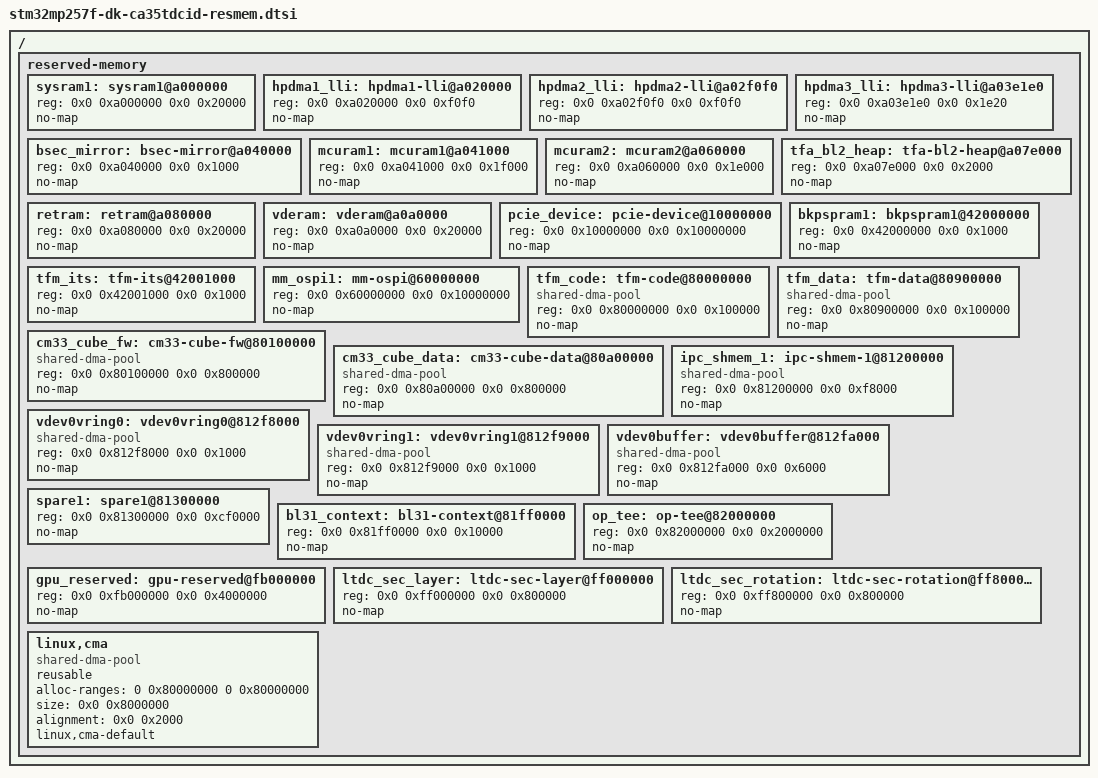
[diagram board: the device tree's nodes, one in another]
// SPDX-License-Identifier: (GPL-2.0-or-later OR BSD-3-Clause)
/*
 * Copyright (C) STMicroelectronics 2022 - All Rights Reserved
 * Author: Loic Pallardy loic.pallardy@foss.st.com for STMicroelectronics.
 */

/*
 * STM32MP25 reserved memory device tree configuration
 * Project : open
 * Generated by XLmx tool version 2.2 - 7/4/2023 9:06:24 AM
 */

/ {
	reserved-memory {
		#address-cells = <2>;
		#size-cells = <2>;
		ranges;

		/* Internal RAM reserved memory declaration */
		sysram1: sysram1@a000000 {
			reg = <0x0 0xa000000 0x0 0x20000>;
			no-map;
		};

		hpdma1_lli: hpdma1-lli@a020000 {
			reg = <0x0 0xa020000 0x0 0xf0f0>;
			no-map;
		};

		hpdma2_lli: hpdma2-lli@a02f0f0 {
			reg = <0x0 0xa02f0f0 0x0 0xf0f0>;
			no-map;
		};

		hpdma3_lli: hpdma3-lli@a03e1e0 {
			reg = <0x0 0xa03e1e0 0x0 0x1e20>;
			no-map;
		};

		bsec_mirror: bsec-mirror@a040000 {
			reg = <0x0 0xa040000 0x0 0x1000>;
			no-map;
		};

		mcuram1: mcuram1@a041000 {
			reg = <0x0 0xa041000 0x0 0x1f000>;
			no-map;
		};

		mcuram2: mcuram2@a060000 {
			reg = <0x0 0xa060000 0x0 0x1e000>;
			no-map;
		};

		tfa_bl2_heap: tfa-bl2-heap@a07e000 {
			reg = <0x0 0xa07e000 0x0 0x2000>;
			no-map;
		};

		retram: retram@a080000 {
			reg = <0x0 0xa080000 0x0 0x20000>;
			no-map;
		};

		vderam: vderam@a0a0000 {
			reg = <0x0 0xa0a0000 0x0 0x20000>;
			no-map;
		};

		/* PCIe reserved memory declaration */
		pcie_device: pcie-device@10000000 {
			reg = <0x0 0x10000000 0x0 0x10000000>;
			no-map;
		};

		/* Backup RAM reserved memory declaration */
		bkpspram1: bkpspram1@42000000 {
			reg = <0x0 0x42000000 0x0 0x1000>;
			no-map;
		};

		tfm_its: tfm-its@42001000 {
			reg = <0x0 0x42001000 0x0 0x1000>;
			no-map;
		};

		/* Octo Memory Manager reserved memory declaration */
		mm_ospi1: mm-ospi@60000000 {
			reg = <0x0 0x60000000 0x0 0x10000000>;
			no-map;
		};

		/* DDR reserved memory declaration */
		tfm_code: tfm-code@80000000 {
			compatible = "shared-dma-pool";
			reg = <0x0 0x80000000 0x0 0x100000>;
			no-map;
		};

		cm33_cube_fw: cm33-cube-fw@80100000 {
			compatible = "shared-dma-pool";
			reg = <0x0 0x80100000 0x0 0x800000>;
			no-map;
		};

		tfm_data: tfm-data@80900000 {
			compatible = "shared-dma-pool";
			reg = <0x0 0x80900000 0x0 0x100000>;
			no-map;
		};

		cm33_cube_data: cm33-cube-data@80a00000 {
			compatible = "shared-dma-pool";
			reg = <0x0 0x80a00000 0x0 0x800000>;
			no-map;
		};

		ipc_shmem_1: ipc-shmem-1@81200000 {
			compatible = "shared-dma-pool";
			reg = <0x0 0x81200000 0x0 0xf8000>;
			no-map;
		};

		vdev0vring0: vdev0vring0@812f8000 {
			compatible = "shared-dma-pool";
			reg = <0x0 0x812f8000 0x0 0x1000>;
			no-map;
		};

		vdev0vring1: vdev0vring1@812f9000 {
			compatible = "shared-dma-pool";
			reg = <0x0 0x812f9000 0x0 0x1000>;
			no-map;
		};

		vdev0buffer: vdev0buffer@812fa000 {
			compatible = "shared-dma-pool";
			reg = <0x0 0x812fa000 0x0 0x6000>;
			no-map;
		};

		spare1: spare1@81300000 {
			reg = <0x0 0x81300000 0x0 0xcf0000>;
			no-map;
		};

		bl31_context: bl31-context@81ff0000 {
			reg = <0x0 0x81ff0000 0x0 0x10000>;
			no-map;
		};

		op_tee: op-tee@82000000 {
			reg = <0x0 0x82000000 0x0 0x2000000>;
			no-map;
		};

		gpu_reserved: gpu-reserved@fb000000 {
			reg = <0x0 0xfb000000 0x0 0x4000000>;
			no-map;
		};

		ltdc_sec_layer: ltdc-sec-layer@ff000000 {
			reg = <0x0 0xff000000 0x0 0x800000>;
			no-map;
		};

		ltdc_sec_rotation: ltdc-sec-rotation@ff800000 {
			reg = <0x0 0xff800000 0x0 0x800000>;
			no-map;
		};

		/* global autoconfigured region for contiguous allocations */
		linux,cma {
			compatible = "shared-dma-pool";
			reusable;
			alloc-ranges = <0 0x80000000 0 0x80000000>;
			size = <0x0 0x8000000>;
			alignment = <0x0 0x2000>;
			linux,cma-default;
		};
	};
};
